# STM32G474VET7 register map
File version: 1.0
Registers are 32-bit, access not given, reset 0x0 unless marked. A register's access mark holds for its fields unless they carry their own. Offsets are from the block's base; [hi:lo] are bit positions; {n}, {i} and the like mark numbered series; 'fields as' and 'values as' point back to an identical list.

## VREFBUF
Base 0x40010030
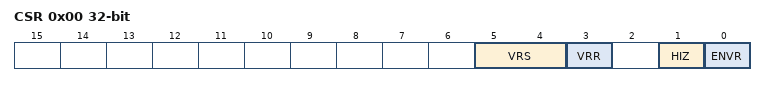
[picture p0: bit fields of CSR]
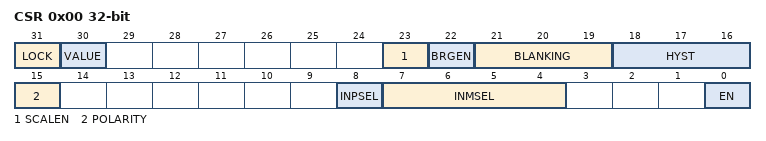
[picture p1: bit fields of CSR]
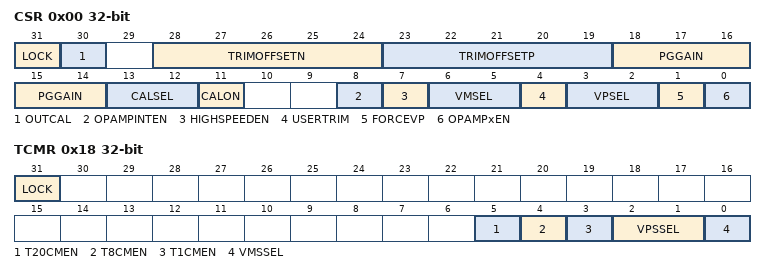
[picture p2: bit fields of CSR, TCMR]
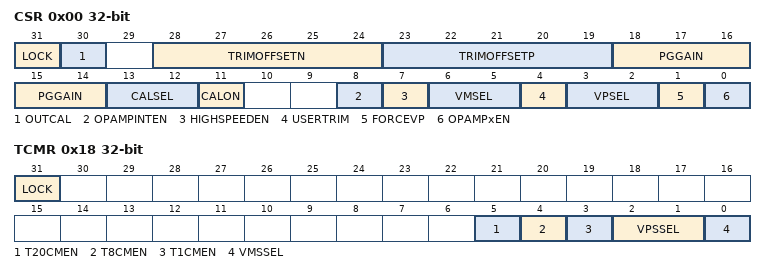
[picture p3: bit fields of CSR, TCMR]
0x00 CSR
  [5:4] VRS, [3] VRR, [1] HIZ, [0] ENVR
0x04 CCR
  [5:0] TRIM

## COMP1
Base 0x40010200
Same registers: COMP2 0x40010204, COMP3 0x40010208, COMP4 0x4001020C, COMP5 0x40010210, COMP6 0x40010214, COMP7 0x40010218
0x00 CSR
  [31] LOCK, [30] VALUE, [23] SCALEN, [22] BRGEN, [21:19] BLANKING, [18:16] HYST, [15] POLARITY, [8] INPSEL, [7:4] INMSEL, [0] EN

## OPAMP
Base 0x40010300
0x00 CSR
  [31] LOCK, [30] OUTCAL, [28:24] TRIMOFFSETN, [23:19] TRIMOFFSETP, [18:14] PGGAIN, [13:12] CALSEL, [11] CALON, [8] OPAMPINTEN, [7] HIGHSPEEDEN, [6:5] VMSEL, [4] USERTRIM, [3:2] VPSEL, [1] FORCEVP, [0] OPAMPxEN
0x18 TCMR
  [31] LOCK, [5] T20CMEN, [4] T8CMEN, [3] T1CMEN, [2:1] VPSSEL, [0] VMSSEL

## OPAMP1
Base 0x40010300
Same registers: OPAMP2 0x40010304, OPAMP3 0x40010308, OPAMP4 0x4001030C, OPAMP5 0x40010310, OPAMP6 0x40010314
0x00 CSR
  [31] LOCK, [30] OUTCAL, [28:24] TRIMOFFSETN, [23:19] TRIMOFFSETP, [18:14] PGGAIN, [13:12] CALSEL, [11] CALON, [8] OPAMPINTEN, [7] HIGHSPEEDEN, [6:5] VMSEL, [4] USERTRIM, [3:2] VPSEL, [1] FORCEVP, [0] OPAMPxEN
0x18 TCMR
  [31] LOCK, [5] T20CMEN, [4] T8CMEN, [3] T1CMEN, [2:1] VPSSEL, [0] VMSSEL

## EXTI
Base 0x40010400
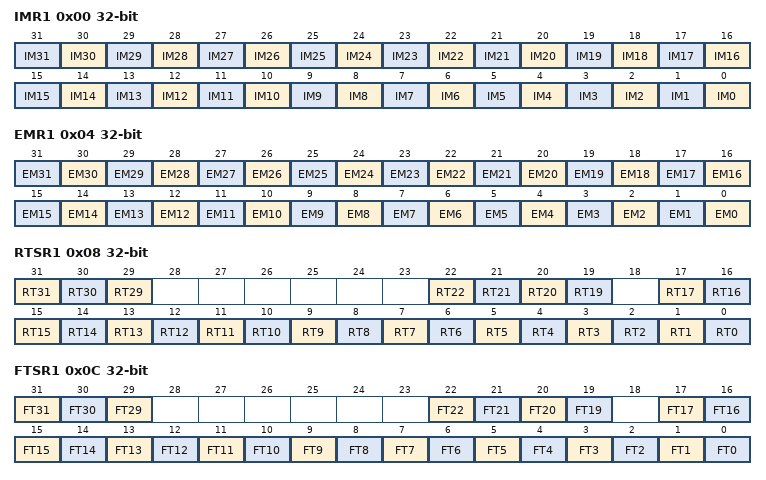
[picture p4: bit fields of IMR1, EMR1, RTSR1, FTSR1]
0x00 IMR1
  [n] IM{n} (n=0..31)
0x04 EMR1
  [n] EM{n} (n=0..31)
0x08 RTSR1
  [31] RT31, [30] RT30, [29] RT29, [n] RT{n} (n=19..22), [n] RT{n} (n=0..17)
0x0C FTSR1
  [31] FT31, [30] FT30, [29] FT29, [n] FT{n} (n=19..22), [n] FT{n} (n=0..17)
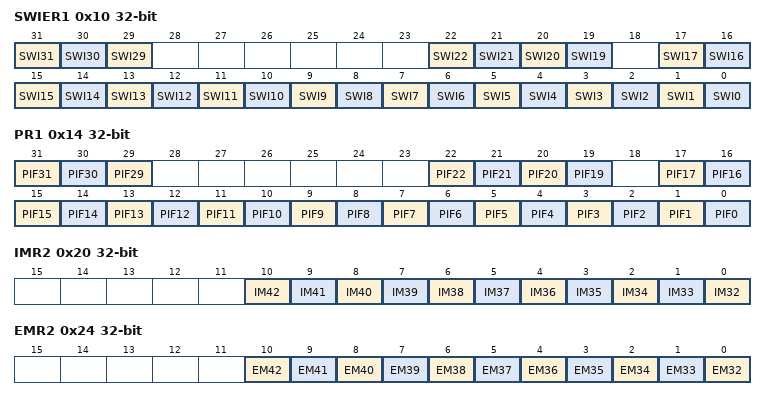
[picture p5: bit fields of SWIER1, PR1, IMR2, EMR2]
0x10 SWIER1
  [31] SWI31, [30] SWI30, [29] SWI29, [n] SWI{n} (n=19..22), [n] SWI{n} (n=0..17)
0x14 PR1
  [31] PIF31, [30] PIF30, [29] PIF29, [n] PIF{n} (n=19..22), [n] PIF{n} (n=0..17)
0x20 IMR2
  [n-32] IM{n} (n=32..42)
0x24 EMR2
  [n-32] EM{n} (n=32..42)
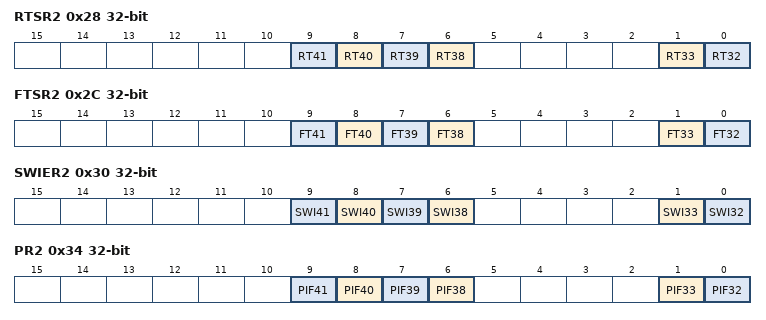
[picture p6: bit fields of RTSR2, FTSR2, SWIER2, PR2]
0x28 RTSR2
  [n-32] RT{n} (n=38..41), [1] RT33, [0] RT32
0x2C FTSR2
  [n-32] FT{n} (n=38..41), [1] FT33, [0] FT32
0x30 SWIER2
  [n-32] SWI{n} (n=38..41), [1] SWI33, [0] SWI32
0x34 PR2
  [n-32] PIF{n} (n=38..41), [1] PIF33, [0] PIF32

## SAI1
Base 0x40015400
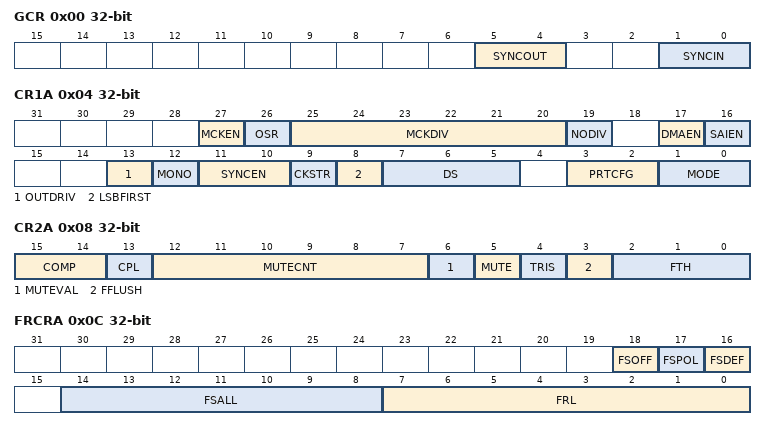
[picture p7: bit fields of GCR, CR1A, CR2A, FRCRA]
0x00 GCR
  [5:4] SYNCOUT, [1:0] SYNCIN
0x04 CR1A
  [27] MCKEN, [26] OSR, [25:20] MCKDIV, [19] NODIV, [17] DMAEN, [16] SAIEN, [13] OUTDRIV, [12] MONO, [11:10] SYNCEN, [9] CKSTR, [8] LSBFIRST, [7:5] DS, [3:2] PRTCFG, [1:0] MODE
0x08 CR2A
  [15:14] COMP, [13] CPL, [12:7] MUTECNT, [6] MUTEVAL, [5] MUTE, [4] TRIS, [3] FFLUSH, [2:0] FTH
0x0C FRCRA
  [18] FSOFF, [17] FSPOL, [16] FSDEF, [14:8] FSALL, [7:0] FRL
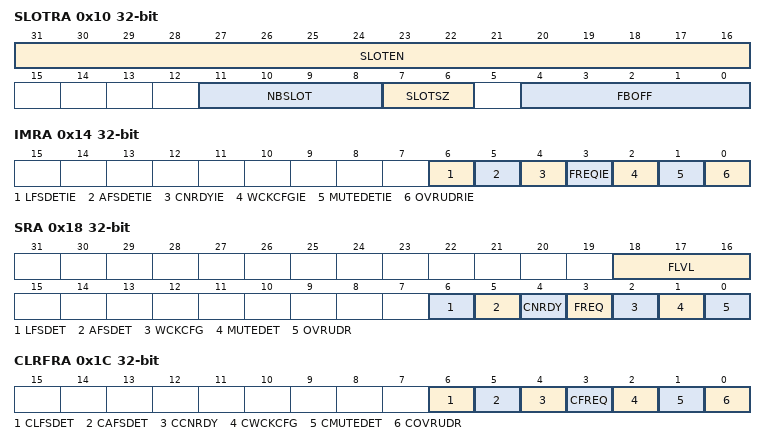
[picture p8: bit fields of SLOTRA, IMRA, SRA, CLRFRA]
0x10 SLOTRA
  [31:16] SLOTEN, [11:8] NBSLOT, [7:6] SLOTSZ, [4:0] FBOFF
0x14 IMRA
  [6] LFSDETIE, [5] AFSDETIE, [4] CNRDYIE, [3] FREQIE, [2] WCKCFGIE, [1] MUTEDETIE, [0] OVRUDRIE
0x18 SRA
  [18:16] FLVL, [6] LFSDET, [5] AFSDET, [4] CNRDY, [3] FREQ, [2] WCKCFG, [1] MUTEDET, [0] OVRUDR
0x1C CLRFRA
  [6] CLFSDET, [5] CAFSDET, [4] CCNRDY, [3] CFREQ, [2] CWCKCFG, [1] CMUTEDET, [0] COVRUDR
0x20 DRA
  [31:0] DATA
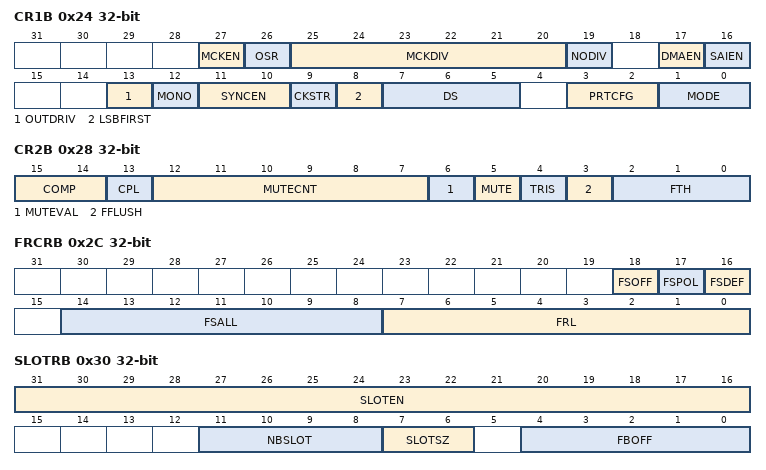
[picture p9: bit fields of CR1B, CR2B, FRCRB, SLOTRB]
0x24 CR1B
  fields as CR1A
0x28 CR2B
  fields as CR2A
0x2C FRCRB
  [18] FSOFF, [17] FSPOL, [16] FSDEF, [14:8] FSALL, [7:0] FRL
0x30 SLOTRB
  [31:16] SLOTEN, [11:8] NBSLOT, [7:6] SLOTSZ, [4:0] FBOFF
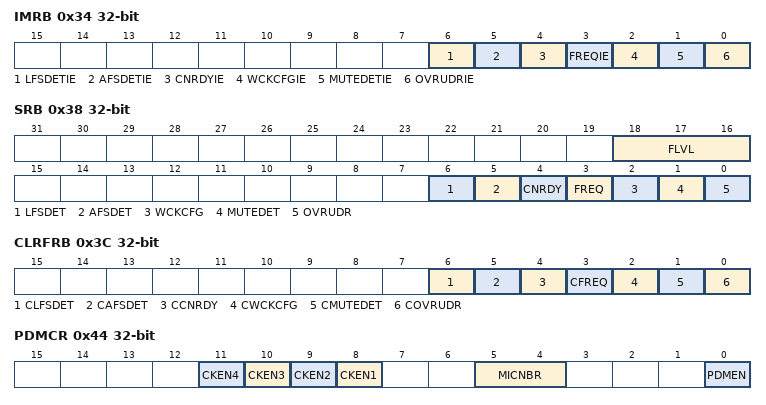
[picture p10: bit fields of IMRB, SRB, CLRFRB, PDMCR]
0x34 IMRB
  fields as IMRA
0x38 SRB
  fields as SRA
0x3C CLRFRB
  fields as CLRFRA
0x40 DRB
  [31:0] DATA
0x44 PDMCR
  [n+7] CKEN{n} (n=1..4), [5:4] MICNBR, [0] PDMEN
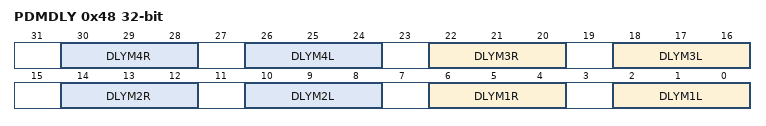
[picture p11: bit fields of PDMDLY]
0x48 PDMDLY
  [8n-2:8n-4] DLYM{n}R (n=1..4), [8n-6:8n-8] DLYM{n}L (n=1..4)

## HRTIM1_TIMA
Base 0x40016880
Same registers: HRTIM1_TIMB 0x40016900, HRTIM1_TIMC 0x40016980, HRTIM1_TIMD 0x40016A00, HRTIM1_TIME 0x40016A80, HRTIM1_TIMF 0x40016B00
0x00 TIMxCR
0x04 TIMxISR
0x08 TIMxICR
0x0C TIMxDIER
0x10 CNTxR
0x14 PERxR
0x18 REPxR
0x1C CMP1xR
0x20 CMP1CxR
{0x1C+4i} CMP{i}xR (i=2..4)
0x30 CPT1xR
0x34 CPT2xR
0x38 DTxR
0x3C SETx1R
0x40 RSTx1R
0x44 SETx2R
0x48 RSTx2R
0x4C EEFxR1
0x50 EEFxR2
0x54 RSTxR
0x58 CHPxR
0x5C CPT1xCR
0x60 CPT2xCR
0x64 OUTxR
0x68 FLTxR
0x6C TIMxCR2
0x70 EEFxR3
